AUTOSAR XML (schema 4-0-3)
standard types defined: Boolean, UInt16, UInt32
package /AUTOSAR_Platform/DataConstrs
  range DC_Boolean: raw 0..1
  range DC_UInt16: raw 0..65535
package /PATAC/MSM/ComponentTypes
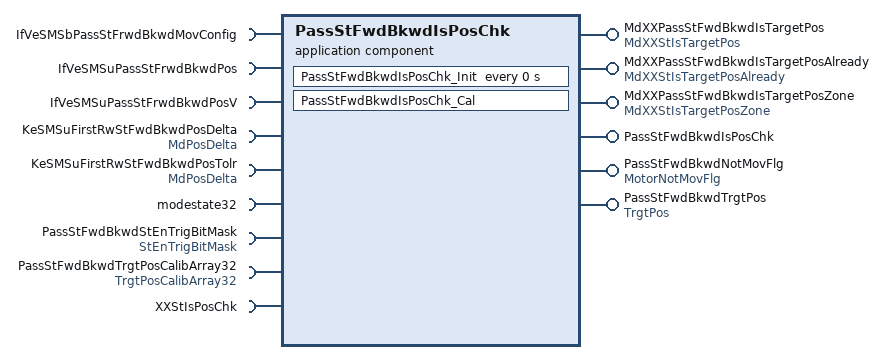
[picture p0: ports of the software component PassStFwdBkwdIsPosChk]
  application sw component type PassStFwdBkwdIsPosChk
    6 x provide port:
      MdXXPassStFwdBkwdIsTargetPos: nonqueued-sender-com-spec{data-element=MdXXStIsTargetPos/Val, init-value=0}, provided-interface=MdXXStIsTargetPos
      MdXXPassStFwdBkwdIsTargetPosAlready: nonqueued-sender-com-spec{data-element=MdXXStIsTargetPosAlready/Val, init-value=0}, provided-interface=MdXXStIsTargetPosAlready
      MdXXPassStFwdBkwdIsTargetPosZone: nonqueued-sender-com-spec{data-element=MdXXStIsTargetPosZone/Val, init-value=0}, provided-interface=MdXXStIsTargetPosZone
      PassStFwdBkwdIsPosChk: server-com-spec{operation=PassStFwdBkwdIsPosChk/Cal, queue-length=1}, provided-interface=PassStFwdBkwdIsPosChk
      PassStFwdBkwdNotMovFlg: nonqueued-sender-com-spec{data-element=MotorNotMovFlg/Val, init-value=0}, provided-interface=MotorNotMovFlg
      PassStFwdBkwdTrgtPos: nonqueued-sender-com-spec{data-element=TrgtPos/Val, init-value=4095}, provided-interface=TrgtPos
    9 x require port:
      IfVeSMSbPassStFrwdBkwdMovConfig: nonqueued-receiver-com-spec{data-element=IfVeSMSbPassStFrwdBkwdMovConfig/Val, filter=data-filter-type=ALWAYS, init-value=0}, required-interface=IfVeSMSbPassStFrwdBkwdMovConfig
      IfVeSMSuPassStFrwdBkwdPos: nonqueued-receiver-com-spec{data-element=IfVeSMSuPassStFrwdBkwdPos/Val, filter=data-filter-type=ALWAYS, init-value=0}, required-interface=IfVeSMSuPassStFrwdBkwdPos
      IfVeSMSuPassStFrwdBkwdPosV: nonqueued-receiver-com-spec{data-element=IfVeSMSuPassStFrwdBkwdPosV/Val, filter=data-filter-type=ALWAYS, init-value=0}, required-interface=IfVeSMSuPassStFrwdBkwdPosV
      KeSMSuFirstRwStFwdBkwdPosDelta: parameter-require-com-spec{init-value=150, parameter=Val}, required-interface=MdPosDelta
      KeSMSuFirstRwStFwdBkwdPosTolr: parameter-require-com-spec{init-value=150, parameter=Val}, required-interface=MdPosDelta
      modestate32: nonqueued-receiver-com-spec{data-element=modestate32/Val, filter=data-filter-type=ALWAYS, init-value=0}, required-interface=modestate32
      PassStFwdBkwdStEnTrigBitMask: nonqueued-receiver-com-spec{data-element=StEnTrigBitMask/Val, filter=data-filter-type=ALWAYS, init-value=0}, required-interface=StEnTrigBitMask
      PassStFwdBkwdTrgtPosCalibArray32: nonqueued-receiver-com-spec{data-element=TrgtPosArray32, filter=data-filter-type=ALWAYS, init-value=96 x 4095}, required-interface=TrgtPosCalibArray32
      XXStIsPosChk: client-com-spec=XXStIsPosChk/Cal, required-interface=XXStIsPosChk
    behavior PassStFwdBkwdIsPosChk_InternalBehavior
      operation invoked event OIT_PassStFwdBkwdIsPosChk_Cal_PassStFwdBkwdIsPosChk_Cal: start-on-event=PassStFwdBkwdIsPosChk_Cal, operation=PassStFwdBkwdIsPosChk.Cal
      timing event PassStFwdBkwdIsPosChk_InitEvent: start-on-event=PassStFwdBkwdIsPosChk_Init, period=0
      runnable PassStFwdBkwdIsPosChk_Cal
        data-receive-point-by-arguments:
          6 x access:
            REC_IfVeSMSbPassStFrwdBkwdMovConfig_Val: accessed-variable=IfVeSMSbPassStFrwdBkwdMovConfig.Val
            REC_IfVeSMSuPassStFrwdBkwdPos_Val: accessed-variable=IfVeSMSuPassStFrwdBkwdPos.Val
            REC_IfVeSMSuPassStFrwdBkwdPosV_Val: accessed-variable=IfVeSMSuPassStFrwdBkwdPosV.Val
            REC_modestate32_Val: accessed-variable=modestate32.Val
            REC_PassStFwdBkwdStEnTrigBitMask_Val: accessed-variable=PassStFwdBkwdStEnTrigBitMask.Val
            REC_PassStFwdBkwdTrgtPosCalibArray32_TrgtPosArray32: accessed-variable=PassStFwdBkwdTrgtPosCalibArray32.TrgtPosArray32
        data-send-points:
          5 x access:
            SEND_MdXXPassStFwdBkwdIsTargetPos_Val: accessed-variable=MdXXPassStFwdBkwdIsTargetPos.Val
            SEND_MdXXPassStFwdBkwdIsTargetPosAlready_Val: accessed-variable=MdXXPassStFwdBkwdIsTargetPosAlready.Val
            SEND_MdXXPassStFwdBkwdIsTargetPosZone_Val: accessed-variable=MdXXPassStFwdBkwdIsTargetPosZone.Val
            SEND_PassStFwdBkwdNotMovFlg_Val: accessed-variable=PassStFwdBkwdNotMovFlg.Val
            SEND_PassStFwdBkwdTrgtPos_Val: accessed-variable=PassStFwdBkwdTrgtPos.Val
        parameter access PA_KeSMSuFirstRwStFwdBkwdPosDelta_Val: accessed-parameter=KeSMSuFirstRwStFwdBkwdPosDelta.Val
        parameter access PA_KeSMSuFirstRwStFwdBkwdPosTolr_Val: accessed-parameter=KeSMSuFirstRwStFwdBkwdPosTolr.Val
        sync call SC_XXStIsPosChk_Cal: operation=XXStIsPosChk.Cal, timeout=0
      runnable PassStFwdBkwdIsPosChk_Init
        parameter access PA_KeSMSuFirstRwStFwdBkwdPosDelta_Val: accessed-parameter=KeSMSuFirstRwStFwdBkwdPosDelta.Val
        parameter access PA_KeSMSuFirstRwStFwdBkwdPosTolr_Val: accessed-parameter=KeSMSuFirstRwStFwdBkwdPosTolr.Val
  swc implementation PassStFwdBkwdIsPosChk_Implementation: behavior=PassStFwdBkwdIsPosChk_InternalBehavior
    code-descriptors:
      code Default: artifact-descriptors=autosar-engineering-object={short-label=Default, category=SWSRC}
package /PATAC/MSM/ModeAdjust/CalPortInterface
  parameter interface MdPosDelta
    parameter data prototype Val: sw-calibration-access=READ-WRITE, type=UInt16
package /PATAC/MSM/ModeAdjust/DataType
  impl type TrgtPosCalibArray32: category=ARRAY, sw-calibration-access=READ-ONLY, type-emitter=RTE  # 0:pos 1:max 2:min
    element Element: array-size=96, array-size-semantics=FIXED-SIZE, implementation-data-type=UInt16, invalid-value=0
package /PATAC/MSM/ModeAdjust/Interfaces
  sender receiver interface IfVeSMSuPassStFrwdBkwdPosV: invalidation-policy{data-element=IfVeSMSuPassStFrwdBkwdPosV/Val, handle-invalid=DONT-INVALIDATE}
    data Val: type=Implementation/Boolean
package /PATAC/MSM/ModeAdjust/PortInterface
  client server interface PassStFwdBkwdIsPosChk
    operation Cal
  client server interface XXStIsPosChk
    operation Cal
      13 x arg, all with server-argument-impl-policy=USE-ARGUMENT-TYPE:
        MdCalibArray32: type=TrgtPosCalibArray32, direction=IN
        Pos: type=UInt16, direction=IN
        PosV: type=DataTypes/Boolean, direction=IN
        MovConfig: type=DataTypes/Boolean, direction=IN
        modestate32: type=UInt32, direction=IN
        IsPos: type=UInt32, direction=OUT
        IsPosAlready: type=UInt32, direction=OUT
        IsPosZone: type=UInt32, direction=OUT
        NotMovFlg: type=DataTypes/Boolean, direction=OUT
        StTrgtPos: type=UInt16, direction=OUT
        PosDelta: type=UInt16, direction=IN
        PosTolr: type=UInt16, direction=IN
        StBitMask: type=UInt32, direction=IN
  7 x sender receiver interface:
    MdXXStIsTargetPos: invalidation-policy{data-element=MdXXStIsTargetPos/Val, handle-invalid=DONT-INVALIDATE}
      data Val: type=UInt32
    MdXXStIsTargetPosAlready: invalidation-policy{data-element=MdXXStIsTargetPosAlready/Val, handle-invalid=DONT-INVALIDATE}
      data Val: type=UInt32
    MdXXStIsTargetPosZone: invalidation-policy{data-element=MdXXStIsTargetPosZone/Val, handle-invalid=DONT-INVALIDATE}
      data Val: type=UInt32
    modestate32: invalidation-policy{data-element=modestate32/Val, handle-invalid=DONT-INVALIDATE}
      data Val: type=UInt32
    MotorNotMovFlg: invalidation-policy{data-element=MotorNotMovFlg/Val, handle-invalid=DONT-INVALIDATE}
      data Val: type=Implementation/Boolean
    StEnTrigBitMask: invalidation-policy{data-element=StEnTrigBitMask/Val, handle-invalid=DONT-INVALIDATE}
      data Val: type=UInt32
    TrgtPosCalibArray32: invalidation-policy{data-element=TrgtPosArray32, handle-invalid=DONT-INVALIDATE}
      data TrgtPosArray32: type=TrgtPosCalibArray32  # 0:Pos 1:Max 2:Min
package /PATAC/MSM/PortInterfaces
  sender receiver interface IfVeSMSbPassStFrwdBkwdMovConfig: invalidation-policy{data-element=IfVeSMSbPassStFrwdBkwdMovConfig/Val, handle-invalid=DONT-INVALIDATE}
    data Val: type=Implementation/Boolean
  sender receiver interface IfVeSMSuPassStFrwdBkwdPos: invalidation-policy{data-element=IfVeSMSuPassStFrwdBkwdPos/Val, handle-invalid=DONT-INVALIDATE}
    data Val: type=UInt16
  sender receiver interface TrgtPos: invalidation-policy{data-element=TrgtPos/Val, handle-invalid=DONT-INVALIDATE}
    data Val: type=UInt16
